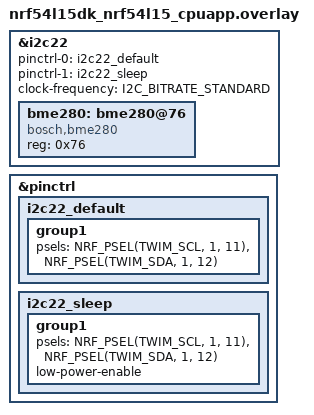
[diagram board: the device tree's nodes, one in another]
&i2c22 {
       status = "okay";
       pinctrl-0 = <&i2c22_default>;
       pinctrl-1 = <&i2c22_sleep>;
       pinctrl-names = "default", "sleep";
       clock-frequency = <I2C_BITRATE_STANDARD>;
       bme280: bme280@76 {
            compatible = "bosch,bme280";
            reg = <0x76>;
       };
};

&pinctrl {
         i2c22_default: i2c22_default {
                 group1  {
                         psels = <NRF_PSEL(TWIM_SCL, 1, 11)>,
                                 <NRF_PSEL(TWIM_SDA, 1, 12)>;
                 };
         };

           i2c22_sleep: i2c22_sleep {
                 group1  {
                         psels = <NRF_PSEL(TWIM_SCL, 1, 11)>,
                                 <NRF_PSEL(TWIM_SDA, 1, 12)>;
                         low-power-enable;
                 };
         };
};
